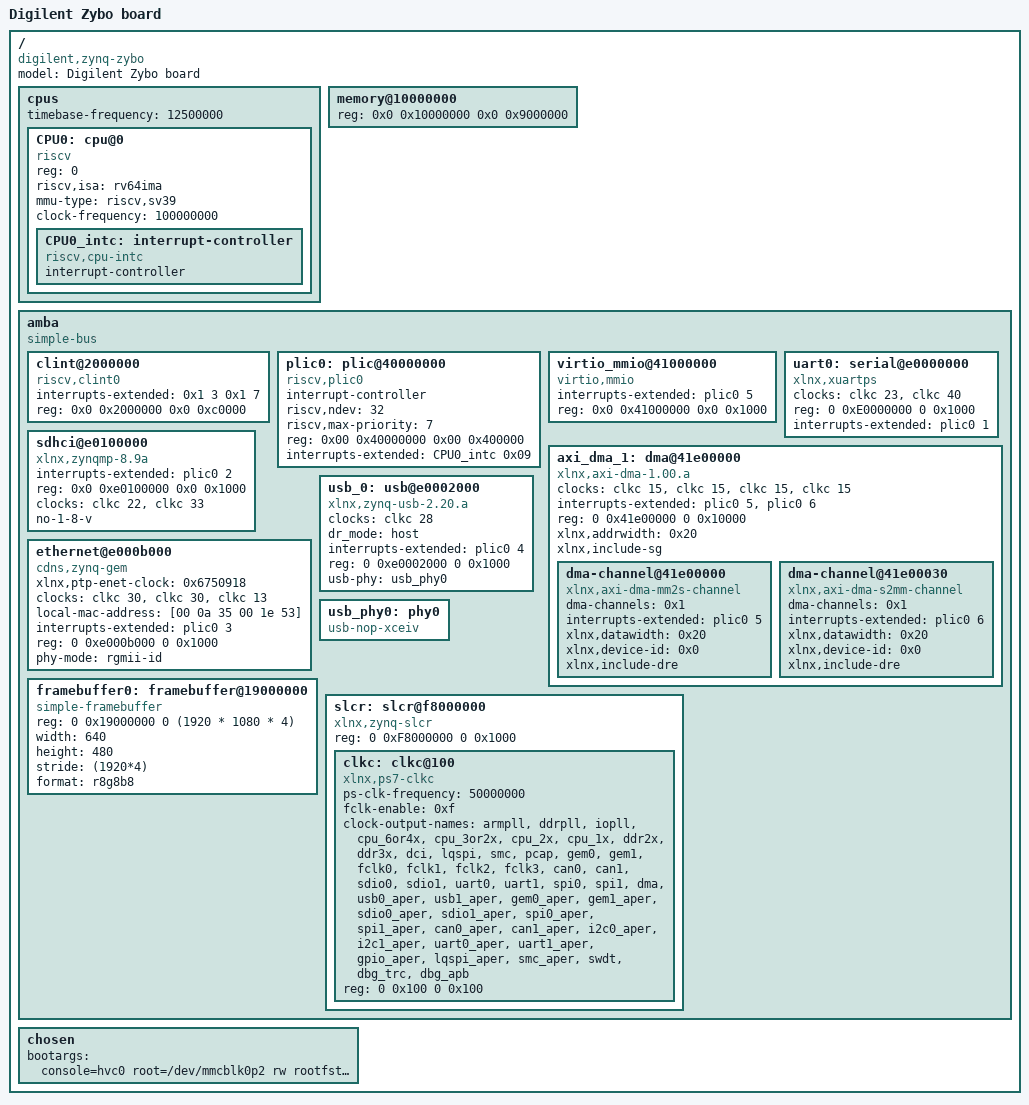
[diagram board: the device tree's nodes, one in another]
/dts-v1/;

/ {
  #address-cells = <2>;
  #size-cells = <2>;

  model = "Digilent Zybo board";
  compatible = "digilent,zynq-zybo", "xlnx,zynq-7000";

  cpus {
    #address-cells = <1>;
    #size-cells = <0>;
    timebase-frequency = <12500000>;
    
    CPU0: cpu@0 {
      device_type = "cpu";
      reg = <0>;
      status = "okay";
      compatible = "riscv";
      riscv,isa = "rv64ima";
      mmu-type = "riscv,sv39";
      clock-frequency = <100000000>;
      CPU0_intc: interrupt-controller {
        #interrupt-cells = <1>;
        interrupt-controller;
        compatible = "riscv,cpu-intc";
      };
    };
  };
  memory@10000000 {
    device_type = "memory";
    reg = <0x0 0x10000000 0x0 0x9000000 >;
  };
  amba: amba {
    #interrupt-cells = <1>;
    #address-cells = <2>;
    #size-cells = <2>;
    compatible =  "simple-bus";
    ranges;
    clint@2000000 {
      compatible = "riscv,clint0";
      interrupts-extended = <0x1 3 0x1 7 >;
      reg = <0x0 0x2000000 0x0 0xc0000>;
    };

    plic0: plic@40000000 {
        #interrupt-cells = <1>;
      interrupt-controller;
      compatible = "riscv,plic0";
      riscv,ndev = <32>;
      riscv,max-priority = <7>;
      reg-names = "control";
      reg = <0x00 0x40000000 0x00 0x400000>;
      interrupts-extended = <&CPU0_intc 0x09>;
    };
    virtio_mmio@41000000{
           status = "okay";
        #interrupt-cells = <1>;
          interrupts-extended = <&plic0 5>;
    		  reg = <0x0 0x41000000 0x0 0x1000>;
    	   compatible = "virtio,mmio";
	     };
        uart0: serial@e0000000 {
            status = "okay";
            #interrupt-cells = <1>;
            compatible = "xlnx,xuartps", "cdns,uart-r1p8";
            clocks = <&clkc 23>, <&clkc 40>;
            clock-names = "uart_clk", "pclk";
            reg = <0 0xE0000000 0 0x1000>;
            interrupts-extended = <&plic0 1>;
        };
    sdhci@e0100000 {
        #interrupt-cells = <1>;
        status= "okay";
        compatible = "xlnx,zynqmp-8.9a", "arasan,sdhci-8.9a";
        interrupts-extended = <&plic0 2>;
        reg = <0x0 0xe0100000 0x0 0x1000>;
        clock-names = "clk_xin", "clk_ahb";
        clocks = <&clkc 22>, <&clkc 33>; 
        no-1-8-v;
    
    };
    axi_dma_1: dma@41e00000 {
                       #interrupt-cells = <1>;
                       #dma-cells = <1>;
                       clock-names = "s_axi_lite_aclk", "m_axi_sg_aclk", "m_axi_mm2s_aclk", "m_axi_s2mm_aclk";
                       clocks = <&clkc 15>, <&clkc 15>, <&clkc 15>, <&clkc 15>;
                       compatible = "xlnx,axi-dma-1.00.a";
                       interrupts-extended = <&plic0 5 &plic0 6>;
                       reg = <0 0x41e00000 0 0x10000>;
                       xlnx,addrwidth = <0x20>;
                       xlnx,include-sg ;
                       dma-channel@41e00000 {
                               compatible = "xlnx,axi-dma-mm2s-channel";
                               dma-channels = <0x1>;
                               interrupts-extended = <&plic0 5>;
                               xlnx,datawidth = <0x20>;
                               xlnx,device-id = <0x0>;
                               xlnx,include-dre ;
                       };
                       dma-channel@41e00030 {
                               compatible = "xlnx,axi-dma-s2mm-channel";
                               dma-channels = <0x1>;
                               interrupts-extended = <&plic0 6>;
                               xlnx,datawidth = <0x20>;
                               xlnx,device-id = <0x0>;
                               xlnx,include-dre ;
                       };
               };

    ethernet@e000b000 {
      #interrupt-cells = <1>;
      xlnx,ptp-enet-clock = <0x6750918>;
      compatible = "cdns,zynq-gem", "cdns,gem";
      clocks =< &clkc 30>, <&clkc 30>, <&clkc 13>;
      local-mac-address = [00 0a 35 00 1e 53];
      clock-names = "pclk", "hclk", "tx_clk";
      status = "okay";
      interrupts-extended = <&plic0 3>;
      reg = <0 0xe000b000 0 0x1000>;
      phy-mode = "rgmii-id";
    };

    usb_0: usb@e0002000 {
     #interrupt-cells = <1>;
         compatible = "xlnx,zynq-usb-2.20.a", "chipidea,usb2";
         clocks = <&clkc 28>;
         dr_mode = "host";
         interrupts-extended = <&plic0  4>;
         reg = <0 0xe0002000 0 0x1000>;
         usb-phy = <&usb_phy0>;
     }; 
     usb_phy0: phy0 {
        #phy-cells = <0>;
        compatible = "usb-nop-xceiv";
    };
    framebuffer0: framebuffer@19000000 {
       compatible = "simple-framebuffer";
      reg = <0 0x19000000 0 (1920 * 1080 * 4)>;
      width = <640>;
        height = <480>;
        stride = <(1920*4)>;
        format = "r8g8b8";
    };
    slcr: slcr@f8000000 {
         #address-cells = <2>;
          #size-cells = <2>;
			compatible = "xlnx,zynq-slcr", "syscon", "simple-mfd";
			reg = <0 0xF8000000 0 0x1000>;
			ranges;
			clkc: clkc@100 {
				#clock-cells = <1>;
				compatible = "xlnx,ps7-clkc";
				ps-clk-frequency = <50000000>;
				fclk-enable = <0xf>;
				clock-output-names = "armpll", "ddrpll", "iopll", "cpu_6or4x",
						"cpu_3or2x", "cpu_2x", "cpu_1x", "ddr2x", "ddr3x",
						"dci", "lqspi", "smc", "pcap", "gem0", "gem1",
						"fclk0", "fclk1", "fclk2", "fclk3", "can0", "can1",
						"sdio0", "sdio1", "uart0", "uart1", "spi0", "spi1",
						"dma", "usb0_aper", "usb1_aper", "gem0_aper",
						"gem1_aper", "sdio0_aper", "sdio1_aper",
						"spi0_aper", "spi1_aper", "can0_aper", "can1_aper",
						"i2c0_aper", "i2c1_aper", "uart0_aper", "uart1_aper",
						"gpio_aper", "lqspi_aper", "smc_aper", "swdt",
						"dbg_trc", "dbg_apb";
				reg = <0 0x100 0 0x100>;
			};

		};
  };

  chosen {
    // bootargs = "root=/dev/vda rw rootwait console=hvc0 ";
  //   bootargs = "root=/dev/vda rw rootwait console=tty0 ";
   //    bootargs = "console=hvc0 root=/dev/mmcblk0p2 rw rootfstype=ext4 rootwait";
      bootargs = "console=hvc0 root=/dev/mmcblk0p2 rw rootfstype=ext4 rootwait";
     // bootargs = "root=/dev/ram rw rootfstype=ramfs console=hvc0 sdhci.debug_quirks=96";
    //bootargs = "root=/dev/mmcblk0p2 rootwait rw  console=hvc0 sdhci.debug_quirks=96";
   // bootargs = "root=/dev/sda rw  console=hvc0";
  };


};

